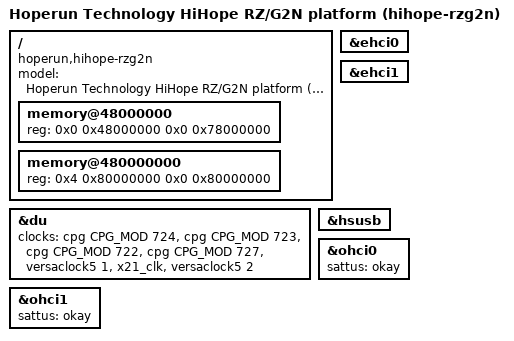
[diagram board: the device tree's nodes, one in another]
// SPDX-License-Identifier: GPL-2.0
/*
 * Device Tree Source for the HiHope RZ/G2N board
 *
 * Copyright (C) 2019 Renesas Electronics Corporation
 */

/dts-v1/;
#include "r8a774b1.dtsi"
#include "hihope-common.dtsi"

/ {
	model = "Hoperun Technology HiHope RZ/G2N platform (hihope-rzg2n)";
	compatible = "hoperun,hihope-rzg2n", "renesas,r8a774b1";

	memory@48000000 {
		device_type = "memory";
		/* first 128MB is reserved for secure area. */
		reg = <0x0 0x48000000 0x0 0x78000000>;
	};

	memory@480000000 {
		device_type = "memory";
		reg = <0x4 0x80000000 0x0 0x80000000>;
	};
};

&du {
	clocks = <&cpg CPG_MOD 724>,
		 <&cpg CPG_MOD 723>,
		 <&cpg CPG_MOD 722>,
		 <&cpg CPG_MOD 727>,
		 <&versaclock5 1>,
		 <&x21_clk>,
		 <&versaclock5 2>;
	clock-names = "du.0", "du.1", "du.2", "lvds.0",
		      "dclkin.0", "dclkin.1", "dclkin.2";
};

&ehci0 {
	status = "okay";
};

&ehci1 {
	status = "okay";
};

&hsusb {
	status = "okay";
};

&ohci0 {
	sattus = "okay";
};

&ohci1 {
	sattus = "okay";
};
